# DDR16SS_DDR16SS_CTLPHY_WRAP_CTL_CFG_CTLCFG_0F308000h register map
Vendor: Texas Instruments
Peripheral module from a debugger description file (folder am62L).
Registers are 32-bit, read-write, reset 0x0 unless marked. A register's access mark holds for its fields unless they carry their own. Offsets are as the file gives them; lines under a group give offsets from that group; [hi:lo] are bit positions; {n}, {i} and the like mark numbered series; 'fields as' and 'values as' point back to an identical list; <NAME> marks a mode.

## DDR16SS_CTLPHY_WRAP_CTL_CFG_CTLCFG (part 1 of 11)
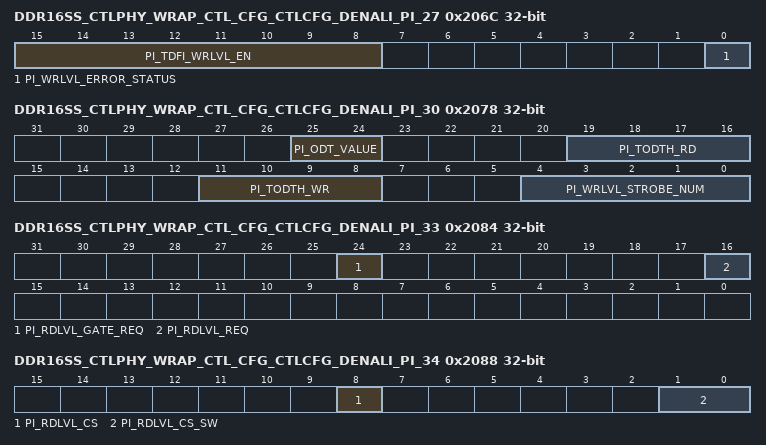
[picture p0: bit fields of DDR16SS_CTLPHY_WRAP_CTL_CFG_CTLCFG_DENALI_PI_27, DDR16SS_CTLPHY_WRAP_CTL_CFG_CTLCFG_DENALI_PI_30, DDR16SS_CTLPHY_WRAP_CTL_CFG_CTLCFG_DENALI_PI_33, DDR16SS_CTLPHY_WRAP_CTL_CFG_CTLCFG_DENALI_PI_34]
0x206C DDR16SS_CTLPHY_WRAP_CTL_CFG_CTLCFG_DENALI_PI_27 access per field
  [15:8] PI_TDFI_WRLVL_EN rw — Defines the DFI tWRLVL_EN timing parameter [in DFI clocks], the minimum cycles from a dfi_wrlvl_en assertion to the first dfi_wrlvl_strobe assertion. Reset Source: ctl_amod_g_rst_n
  [0] PI_WRLVL_ERROR_STATUS ro — Holds the error associated with the write level error interrupt. Bit [0] set indicates a TDFI_WRLVL_MAX parameter violation and bit [1] set indicates a TDFI_WRLVL_RESP parameter violation. READ-ONLY Reset Source: ctl_amod_g_rst_n
0x2070 DDR16SS_CTLPHY_WRAP_CTL_CFG_CTLCFG_DENALI_PI_28
  [31:0] PI_TDFI_WRLVL_RESP — Defines the DFI tWRLVL_RESP timing parameter [in DFI clocks], the maximum cycles between a dfi_wrlvl_req assertion and a dfi_wrlvl_en assertion. Reset Source: ctl_amod_g_rst_n
0x2074 DDR16SS_CTLPHY_WRAP_CTL_CFG_CTLCFG_DENALI_PI_29
  [31:0] PI_TDFI_WRLVL_MAX — Defines the DFI tWRLVL_MAX timing parameter [in DFI clocks], the maximum cycles between a dfi_wrlvl_en assertion and a valid dfi_wrlvl_resp. Reset Source: ctl_amod_g_rst_n
0x2078 DDR16SS_CTLPHY_WRAP_CTL_CFG_CTLCFG_DENALI_PI_30
  [25:24] PI_ODT_VALUE — When using LPDDR4, this value will be driven out on the dfi_odt signal. Reset Source: ctl_amod_g_rst_n
  [19:16] PI_TODTH_RD — Defines the minimum DRAM cycles of ODT high time for a read command, in memory clocks. Reset Source: ctl_amod_g_rst_n
  [11:8] PI_TODTH_WR — Defines the minimum DRAM cycles of ODT high time for a write command, in memory clocks. Reset Source: ctl_amod_g_rst_n
  [4:0] PI_WRLVL_STROBE_NUM — Defines the number of write leveling strobes generated. Reset Source: ctl_amod_g_rst_n
0x207C DDR16SS_CTLPHY_WRAP_CTL_CFG_CTLCFG_DENALI_PI_31
  [1:0] PI_ADDRESS_MIRRORING — Indicates which chip selects support address mirroring. Bit [0] controls cs0, bit [1] controls cs1, etc. Set each bit to 1 to enable. Reset Source: ctl_amod_g_rst_n
0x2080 DDR16SS_CTLPHY_WRAP_CTL_CFG_CTLCFG_DENALI_PI_32
  [25:0] PI_CA_PARITY_ERROR_INJECT — Selects bit to corrupt on the CA bus for CA parity error injection. Reset Source: ctl_amod_g_rst_n
0x2084 DDR16SS_CTLPHY_WRAP_CTL_CFG_CTLCFG_DENALI_PI_33 wo
  [24] PI_RDLVL_GATE_REQ — User request to initiate gate training. Set to 1 to trigger. WRITE-ONLY Reset Source: ctl_amod_g_rst_n
  [16] PI_RDLVL_REQ — User request to initiate data eye training. Set to 1 to trigger. WRITE-ONLY Reset Source: ctl_amod_g_rst_n
0x2088 DDR16SS_CTLPHY_WRAP_CTL_CFG_CTLCFG_DENALI_PI_34
  [8] PI_RDLVL_CS — Specifies the target chip select for the data eye training operation initiated through the RDLVL_REQ parameter or the gate training operation initiated through the RDLVL_GATE_REQ parameter. Reset Source: ctl_amod_g_rst_n
  [1:0] PI_RDLVL_CS_SW — Specifies the target chip select for the data eye training operation initiated through the RDLVL_REQ parameter or the gate training operation initiated through the RDLVL_GATE_REQ parameter. Reset Source: ctl_amod_g_rst_n
{0x2000+4i} DDR16SS_CTLPHY_WRAP_CTL_CFG_CTLCFG_DENALI_PI_{i} (i=35..42)
  [31:0] PI_RDLVL_PAT_{i-35} — Non-default pattern {i-35} used for read data eye training of DDR4 or LPDDR4, and read dbi training of DDR4. Reset Source: ctl_amod_g_rst_n
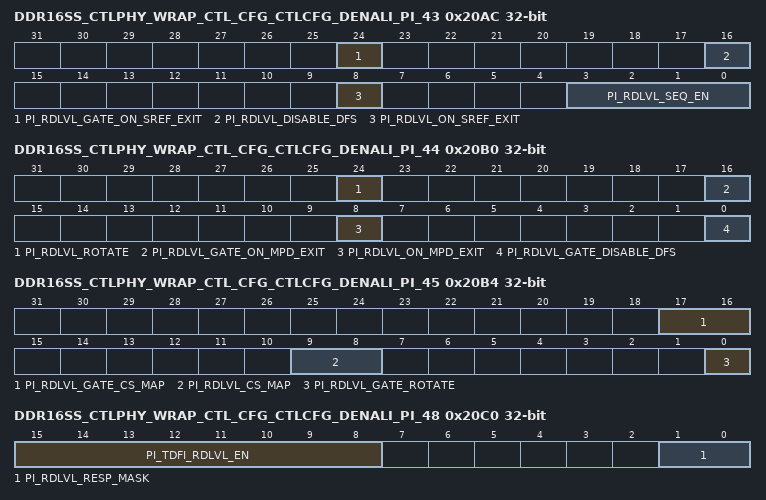
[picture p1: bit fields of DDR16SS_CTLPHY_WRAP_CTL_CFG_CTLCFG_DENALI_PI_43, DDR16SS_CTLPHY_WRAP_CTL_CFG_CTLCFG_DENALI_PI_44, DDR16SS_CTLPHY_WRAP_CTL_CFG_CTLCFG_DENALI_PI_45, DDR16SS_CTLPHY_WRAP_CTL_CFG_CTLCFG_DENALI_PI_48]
0x20AC DDR16SS_CTLPHY_WRAP_CTL_CFG_CTLCFG_DENALI_PI_43
  [24] PI_RDLVL_GATE_ON_SREF_EXIT — Enables automatic gate training on a self-refresh exit. Set to 1 to enable. Reset Source: ctl_amod_g_rst_n
  [16] PI_RDLVL_DISABLE_DFS — Disables automatic data eye training on freq change. Set to 1 to disable rdlvl on dfs,Set to 0 to enable rdlvl on dfs. Reset Source: ctl_amod_g_rst_n
  [8] PI_RDLVL_ON_SREF_EXIT — Enables automatic data eye training on a self-refresh exit. Set to 1 to enable. Reset Source: ctl_amod_g_rst_n
  [3:0] PI_RDLVL_SEQ_EN — Specifies the pattern, format and MPR for data eye training. Reset Source: ctl_amod_g_rst_n
0x20B0 DDR16SS_CTLPHY_WRAP_CTL_CFG_CTLCFG_DENALI_PI_44
  [24] PI_RDLVL_ROTATE — Enables rotational CS for interval data eye training. Set to 1 for rotating CS. Reset Source: ctl_amod_g_rst_n
  [16] PI_RDLVL_GATE_ON_MPD_EXIT — Enables automatic gate training on a maximum power down mode exit. Set to 1 to enable. Reset Source: ctl_amod_g_rst_n
  [8] PI_RDLVL_ON_MPD_EXIT — Enables automatic data eye training on a maximum power down mode exit. Set to 1 to enable. Reset Source: ctl_amod_g_rst_n
  [0] PI_RDLVL_GATE_DISABLE_DFS — Disables automatic gate training on freq change. Set to 1 to disable rdlvl_gate on dfs,Set to 0 to enable rdlvl_gate on dfs. Reset Source: ctl_amod_g_rst_n
0x20B4 DDR16SS_CTLPHY_WRAP_CTL_CFG_CTLCFG_DENALI_PI_45
  [17:16] PI_RDLVL_GATE_CS_MAP — Defines the chip select map for gate training operations. Bit [0] controls cs0, bit [1] controls cs1, etc. Set each bit to 1 to enable chip for gate training. Reset Source: ctl_amod_g_rst_n
  [9:8] PI_RDLVL_CS_MAP — Defines the chip select map for data eye training operations. Bit [0] controls cs0, bit [1] controls cs1, etc. Set each bit to 1 to enable chip for data eye training. Reset Source: ctl_amod_g_rst_n
  [0] PI_RDLVL_GATE_ROTATE — Enables rotational CS for interval gate training. Set to 1 for rotating CS. Reset Source: ctl_amod_g_rst_n
0x20B8 DDR16SS_CTLPHY_WRAP_CTL_CFG_CTLCFG_DENALI_PI_46
  [9:0] PI_TDFI_RDLVL_RR — Defines the DFI tRDLVL_RR timing parameter [in DFI clocks], the minimum cycles between read commands. Reset Source: ctl_amod_g_rst_n
0x20BC DDR16SS_CTLPHY_WRAP_CTL_CFG_CTLCFG_DENALI_PI_47
  [31:0] PI_TDFI_RDLVL_RESP — Defines the DFI tRDLVL_RESP timing parameter [in DFI clocks], the maximum cycles between a dfi_rdlvl_req or dfi_rdlvl_gate_req assertion and a dfi_rdlvl_en or dfi_rdlvl_gate_en assertion. Reset Source: ctl_amod_g_rst_n
0x20C0 DDR16SS_CTLPHY_WRAP_CTL_CFG_CTLCFG_DENALI_PI_48
  [15:8] PI_TDFI_RDLVL_EN — Defines the DFI tRDLVL_EN timing parameter [in DFI clocks], the minimum cycles from a dfi_rdlvl_en or dfi_rdlvl_gate_en assertion to the first read or MRR. Set to 1 means the minium value[1 cycle], set to 0 means the maxium value Reset Source: ctl_amod_g_rst_n
  [1:0] PI_RDLVL_RESP_MASK — Mask for the dfi_rdlvl_resp signal during data eye training. Reset Source: ctl_amod_g_rst_n
0x20C4 DDR16SS_CTLPHY_WRAP_CTL_CFG_CTLCFG_DENALI_PI_49
  [31:0] PI_TDFI_RDLVL_MAX — Defines the DFI tRDLVL_MAX timing parameter [in DFI clocks], the maximum cycles between a dfi_rdlvl_en or dfi_rdlvl_gate_en assertion and a valid dfi_rdlvl_resp. Reset Source: ctl_amod_g_rst_n
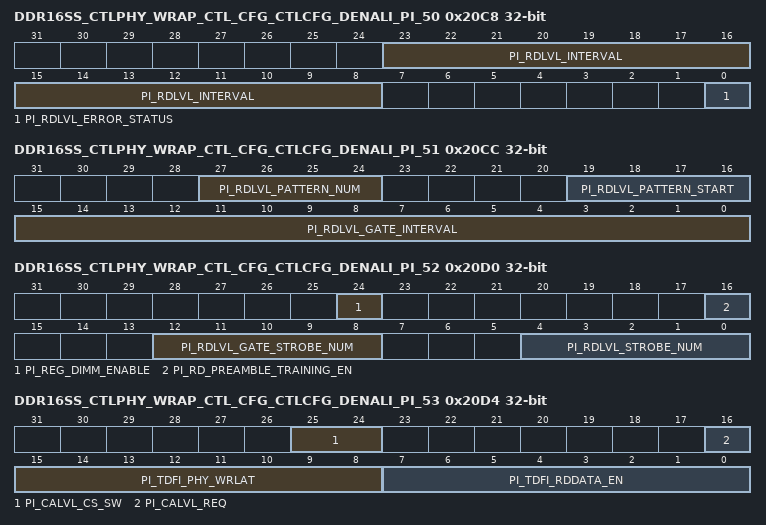
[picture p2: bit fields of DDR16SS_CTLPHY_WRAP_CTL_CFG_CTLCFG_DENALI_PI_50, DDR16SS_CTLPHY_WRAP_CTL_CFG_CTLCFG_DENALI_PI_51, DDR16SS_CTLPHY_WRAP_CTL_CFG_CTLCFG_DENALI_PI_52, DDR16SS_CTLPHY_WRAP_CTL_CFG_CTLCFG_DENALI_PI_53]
0x20C8 DDR16SS_CTLPHY_WRAP_CTL_CFG_CTLCFG_DENALI_PI_50 access per field
  [23:8] PI_RDLVL_INTERVAL rw — Number of long count sequences counted between automatic data eye training commands. Reset Source: ctl_amod_g_rst_n
  [0] PI_RDLVL_ERROR_STATUS ro — Holds the error associated with the data eye training error or gate training error interrupt. Uppermost bit set indicates a TDFI_RDLVL_RESP parameter violation. Next uppermost bit set indicates a TDFI_RDLVL_MAX parameter violation. Lower bits are reserved. READ-ONLY Reset Source: ctl_amod_g_rst_n
0x20CC DDR16SS_CTLPHY_WRAP_CTL_CFG_CTLCFG_DENALI_PI_51
  [27:24] PI_RDLVL_PATTERN_NUM — Defines the number of pattern supported in read leveling. Reset Source: ctl_amod_g_rst_n
  [19:16] PI_RDLVL_PATTERN_START — Defines the start pattern in read leveling. Reset Source: ctl_amod_g_rst_n
  [15:0] PI_RDLVL_GATE_INTERVAL — Number of long count sequences counted between automatic gate training commands. Reset Source: ctl_amod_g_rst_n
0x20D0 DDR16SS_CTLPHY_WRAP_CTL_CFG_CTLCFG_DENALI_PI_52
  [24] PI_REG_DIMM_ENABLE — Enable registered DIMM operation. Set to 1 to enable. Reset Source: ctl_amod_g_rst_n
  [16] PI_RD_PREAMBLE_TRAINING_EN — Enable read preamble training during gate training. Set to 1 to enable. Reset Source: ctl_amod_g_rst_n
  [12:8] PI_RDLVL_GATE_STROBE_NUM — Defines the number of back to back MPC command in one read process in read gate training. Reset Source: ctl_amod_g_rst_n
  [4:0] PI_RDLVL_STROBE_NUM — Defines the number of back to back MPC command in one read process in read eye training. Reset Source: ctl_amod_g_rst_n
0x20D4 DDR16SS_CTLPHY_WRAP_CTL_CFG_CTLCFG_DENALI_PI_53 access per field
  [25:24] PI_CALVL_CS_SW rw — Specifies the target chip select for the CA training operation initiated through the CALVL_REQ parameter. Reset Source: ctl_amod_g_rst_n
  [16] PI_CALVL_REQ wo — User request to initiate CA training. Set to 1 to trigger. WRITE-ONLY Reset Source: ctl_amod_g_rst_n
  [15:8] PI_TDFI_PHY_WRLAT ro — Holds the calculated DFI tPHY_WRLAT timing parameter [in DFI PHY clocks], the maximum cycles between a write command and a dfi_wrdata_en assertion. READ-ONLY Reset Source: ctl_amod_g_rst_n
  [7:0] PI_TDFI_RDDATA_EN ro — Holds the calculated DFI tRDDATA_EN timing parameter [in DFI PHY clocks], the maximum cycles between a read command and a dfi_rddata_en assertion. READ-ONLY Reset Source: ctl_amod_g_rst_n
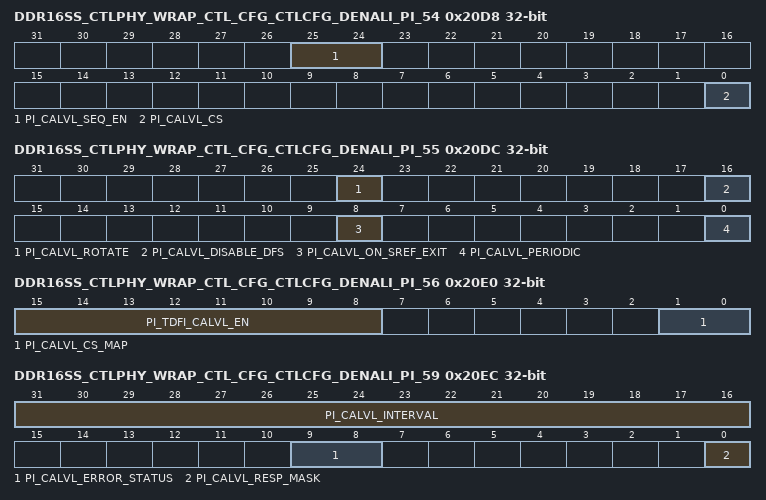
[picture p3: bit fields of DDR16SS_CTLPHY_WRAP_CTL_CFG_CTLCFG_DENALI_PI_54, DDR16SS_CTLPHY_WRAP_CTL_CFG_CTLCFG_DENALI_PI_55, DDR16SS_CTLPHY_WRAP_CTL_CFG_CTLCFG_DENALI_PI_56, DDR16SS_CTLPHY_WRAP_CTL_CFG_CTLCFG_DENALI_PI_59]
0x20D8 DDR16SS_CTLPHY_WRAP_CTL_CFG_CTLCFG_DENALI_PI_54
  [25:24] PI_CALVL_SEQ_EN — Specifies which CA training patterns will be used. Set to 0 for pattern 0 only, set to 1 for patterns 0 and 1, set to 2 for patterns 0, 1 and 2, or set to 3 for all patterns. Reset Source: ctl_amod_g_rst_n
  [0] PI_CALVL_CS — Specifies the target chip select for the CA training operation initiated through the CALVL_REQ parameter. Reset Source: ctl_amod_g_rst_n
0x20DC DDR16SS_CTLPHY_WRAP_CTL_CFG_CTLCFG_DENALI_PI_55
  [24] PI_CALVL_ROTATE — Enables rotational CS for interval CA training. Set to 1 for rotating CS. Reset Source: ctl_amod_g_rst_n
  [16] PI_CALVL_DISABLE_DFS — Disables automatic CA training on freq change. Set to 1 to disable CA training on dfs, Set to 0 to enable CA training . Reset Source: ctl_amod_g_rst_n
  [8] PI_CALVL_ON_SREF_EXIT — Enables automatic CA training on a self-refresh exit. Set to 1 to enable. Reset Source: ctl_amod_g_rst_n
  [0] PI_CALVL_PERIODIC — Enables the use of the dfi_lvl_periodic signal during CA training. Set to 1 to enable. Reset Source: ctl_amod_g_rst_n
0x20E0 DDR16SS_CTLPHY_WRAP_CTL_CFG_CTLCFG_DENALI_PI_56
  [15:8] PI_TDFI_CALVL_EN — Defines the DFI tCALVL_EN timing parameter [in DFI clocks], the minimum cycles between a dfi_calvl_en assertion and a dfi_cke de-assertion. Reset Source: ctl_amod_g_rst_n
  [1:0] PI_CALVL_CS_MAP — Defines the chip select map for CA training operations. Bit [0] controls cs0, bit [1] controls cs1, etc. Set each bit to 1 to enable chip for CA training. Reset Source: ctl_amod_g_rst_n
0x20E4 DDR16SS_CTLPHY_WRAP_CTL_CFG_CTLCFG_DENALI_PI_57
  [31:0] PI_TDFI_CALVL_RESP — Defines the DFI tCALVL_RESP timing parameter [in DFI clocks], the maximum cycles between a dfi_calvl_req assertion and a dfi_calvl_en assertion. Reset Source: ctl_amod_g_rst_n
0x20E8 DDR16SS_CTLPHY_WRAP_CTL_CFG_CTLCFG_DENALI_PI_58
  [31:0] PI_TDFI_CALVL_MAX — Defines the DFI tCALVL_MAX timing parameter [in DFI clocks], the maximum cycles between a dfi_calvl_en assertion and a valid dfi_calvl_resp. Reset Source: ctl_amod_g_rst_n
0x20EC DDR16SS_CTLPHY_WRAP_CTL_CFG_CTLCFG_DENALI_PI_59 access per field
  [31:16] PI_CALVL_INTERVAL rw — Number of long count sequences counted between automatic CA training commands. Reset Source: ctl_amod_g_rst_n
  [9:8] PI_CALVL_ERROR_STATUS ro — Holds the error associated with the CA training error interrupt. Bit [0] set indicates a TDFI_CALVL_RESP parameter violation and bit [1] set indicates a TDFI_CALVL_MAX parameter violation. READ-ONLY Reset Source: ctl_amod_g_rst_n
  [0] PI_CALVL_RESP_MASK rw — Mask for the dfi_calvl_resp signal during CA training. Reset Source: ctl_amod_g_rst_n
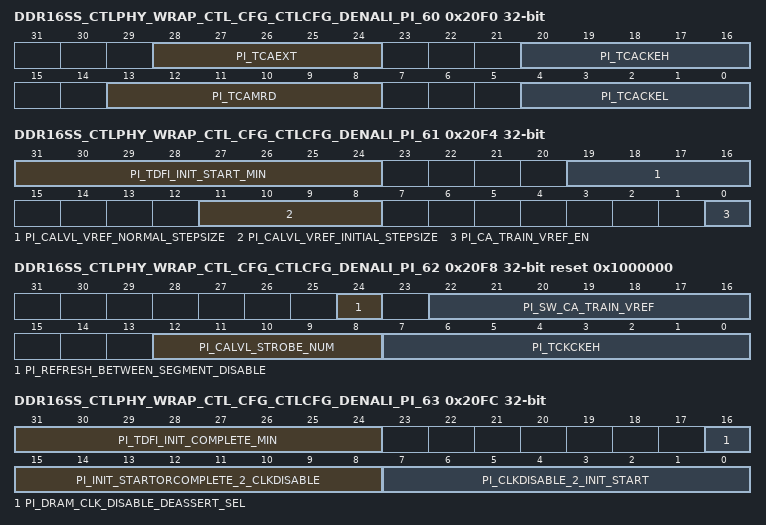
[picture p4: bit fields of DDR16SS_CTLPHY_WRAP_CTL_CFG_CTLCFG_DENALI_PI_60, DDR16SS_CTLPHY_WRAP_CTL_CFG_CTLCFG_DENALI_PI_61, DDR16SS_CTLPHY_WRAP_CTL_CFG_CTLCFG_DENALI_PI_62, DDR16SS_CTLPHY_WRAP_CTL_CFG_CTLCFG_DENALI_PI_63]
0x20F0 DDR16SS_CTLPHY_WRAP_CTL_CFG_CTLCFG_DENALI_PI_60
  [28:24] PI_TCAEXT — DRAM tCAEXT value in memory cycles. Reset Source: ctl_amod_g_rst_n
  [20:16] PI_TCACKEH — DRAM tCACKEH value in memory cycles. Reset Source: ctl_amod_g_rst_n
  [13:8] PI_TCAMRD — DRAM tCAMRD value in memory cycles. Reset Source: ctl_amod_g_rst_n
  [4:0] PI_TCACKEL — DRAM tCACKEL value in memory cycles. Reset Source: ctl_amod_g_rst_n
0x20F4 DDR16SS_CTLPHY_WRAP_CTL_CFG_CTLCFG_DENALI_PI_61
  [31:24] PI_TDFI_INIT_START_MIN — Minimum number of DFI clocks before dfi_init_start can be driven after a previous command/training event. Reset Source: ctl_amod_g_rst_n
  [19:16] PI_CALVL_VREF_NORMAL_STEPSIZE — The adjust step for the post-initial Vref[ca] training. Reset Source: ctl_amod_g_rst_n
  [11:8] PI_CALVL_VREF_INITIAL_STEPSIZE — The adjust step for the initial Vref[ca] training. Reset Source: ctl_amod_g_rst_n
  [0] PI_CA_TRAIN_VREF_EN — Control for VREF training during CA training post power-on initialization. Set to enable VREF training. Reset Source: ctl_amod_g_rst_n
0x20F8 DDR16SS_CTLPHY_WRAP_CTL_CFG_CTLCFG_DENALI_PI_62 reset 0x1000000
  [24] PI_REFRESH_BETWEEN_SEGMENT_DISABLE — Disable the refresh between CA first and second segment training. Set to 1 to disable. Reset Source: ctl_amod_g_rst_n
  [22:16] PI_SW_CA_TRAIN_VREF — The Vref value which is set for SW step by step CA training. Reset Source: ctl_amod_g_rst_n
  [12:8] PI_CALVL_STROBE_NUM — The consecutive dfi_calvl_strobe number when updating the CA vref data. Reset Source: ctl_amod_g_rst_n
  [7:0] PI_TCKCKEH — DRAM tCKELCK Clock and command valid before CKE HIGH. Reset Source: ctl_amod_g_rst_n
0x20FC DDR16SS_CTLPHY_WRAP_CTL_CFG_CTLCFG_DENALI_PI_63
  [31:24] PI_TDFI_INIT_COMPLETE_MIN — Minimum number of DFI clocks from dfi_init_complete to a command/training event. Reset Source: ctl_amod_g_rst_n
  [16] PI_DRAM_CLK_DISABLE_DEASSERT_SEL — Indicate dfi_dram_clk_disable deassert following dfi_init_start deassert or dfi_init_complete assert. Set to 0: dfi_dram_clk_disable deassert following dfi_init_start deassert. Set to 1: dfi_dram_clk_disable deassert following dfi_init_complete assert. Reset Source: ctl_amod_g_rst_n
  [15:8] PI_INIT_STARTORCOMPLETE_2_CLKDISABLE — Defines the delay from deasserting of dfi_init_start or asserting of dfi_init_complete to deasserting of dfi_dram_clk_disable in DFI clock. Reset Source: ctl_amod_g_rst_n
  [7:0] PI_CLKDISABLE_2_INIT_START — Defines the delay from the asserting of dfi_dram_clk_disable to the asserting of dfi_init_start in DFI clock. Reset Source: ctl_amod_g_rst_n
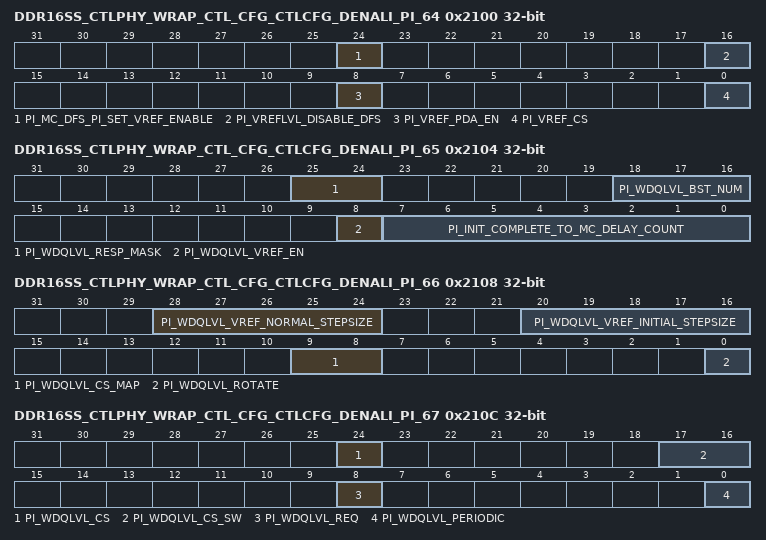
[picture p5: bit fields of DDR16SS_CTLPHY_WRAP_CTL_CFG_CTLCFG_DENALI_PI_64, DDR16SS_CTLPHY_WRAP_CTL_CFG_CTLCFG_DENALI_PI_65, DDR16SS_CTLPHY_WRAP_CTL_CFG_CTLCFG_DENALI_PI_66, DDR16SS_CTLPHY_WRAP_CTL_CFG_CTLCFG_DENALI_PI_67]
0x2100 DDR16SS_CTLPHY_WRAP_CTL_CFG_CTLCFG_DENALI_PI_64
  [24] PI_MC_DFS_PI_SET_VREF_ENABLE — Enable the PI to set VREF value after DFS issued by MC. MR12 and MR14 for LPDDR4. MR6 for DDR4. 1 means disable. Reset Source: ctl_amod_g_rst_n
  [16] PI_VREFLVL_DISABLE_DFS — Disables automatic VREF training on freq change. Set to 1 to disable. Reset Source: ctl_amod_g_rst_n
  [8] PI_VREF_PDA_EN — Enable per-DRAM addressability during VREF training. Set to 1 to enable. Reset Source: ctl_amod_g_rst_n
  [0] PI_VREF_CS — Specifies the target chip select for the VREF training operation. Reset Source: ctl_amod_g_rst_n
0x2104 DDR16SS_CTLPHY_WRAP_CTL_CFG_CTLCFG_DENALI_PI_65
  [25:24] PI_WDQLVL_RESP_MASK — Write DQ training response mask. When set to 1, the dfi_wdqlvl_en of the slice is not asserted. Reset Source: ctl_amod_g_rst_n
  [18:16] PI_WDQLVL_BST_NUM — Defines the number of write/read bursts issued at each step in write DQ training. Reset Source: ctl_amod_g_rst_n
  [8] PI_WDQLVL_VREF_EN — Control for VREF training as part of non-initialization write DQ training. Reset Source: ctl_amod_g_rst_n
  [7:0] PI_INIT_COMPLETE_TO_MC_DELAY_COUNT — It controls the time PI bypass CKE at the beginning of PI mask dfi_init_complete to controller. Reset Source: ctl_amod_g_rst_n
0x2108 DDR16SS_CTLPHY_WRAP_CTL_CFG_CTLCFG_DENALI_PI_66
  [28:24] PI_WDQLVL_VREF_NORMAL_STEPSIZE — Write DQ training vref step size for post_initial training. Reset Source: ctl_amod_g_rst_n
  [20:16] PI_WDQLVL_VREF_INITIAL_STEPSIZE — Write DQ training vref step size for initial training. Reset Source: ctl_amod_g_rst_n
  [9:8] PI_WDQLVL_CS_MAP — Map of CS's included in write DQ training sequence. Reset Source: ctl_amod_g_rst_n
  [0] PI_WDQLVL_ROTATE — Enables write DQ training rotate for interval training. Reset Source: ctl_amod_g_rst_n
0x210C DDR16SS_CTLPHY_WRAP_CTL_CFG_CTLCFG_DENALI_PI_67 access per field
  [24] PI_WDQLVL_CS rw — Write DQ training target chip select. Reset Source: ctl_amod_g_rst_n
  [17:16] PI_WDQLVL_CS_SW rw — Write DQ training target chip select. Reset Source: ctl_amod_g_rst_n
  [8] PI_WDQLVL_REQ wo — SW write to initiate Write DQ training request. WRITE-ONLY Reset Source: ctl_amod_g_rst_n
  [0] PI_WDQLVL_PERIODIC rw — Enables periodic write DQ training. Reset Source: ctl_amod_g_rst_n
0x2110 DDR16SS_CTLPHY_WRAP_CTL_CFG_CTLCFG_DENALI_PI_68
  [7:0] PI_TDFI_WDQLVL_EN — DFI timing param tWDQLVL_EN. Minimum number of DFI clocks required after the write DQ training enable signal is asserted until the first write command may be asserted. Reset Source: ctl_amod_g_rst_n
0x2114 DDR16SS_CTLPHY_WRAP_CTL_CFG_CTLCFG_DENALI_PI_69
  [31:0] PI_TDFI_WDQLVL_RESP — DFI timing param tWDQLVL_RESP. Maximum number of DFI clocks that may occur between a write DQ training request and the associated mode enable. Reset Source: ctl_amod_g_rst_n
0x2118 DDR16SS_CTLPHY_WRAP_CTL_CFG_CTLCFG_DENALI_PI_70
  [31:0] PI_TDFI_WDQLVL_MAX — DFI timing param tWDQLVL_MAX. Maximum number of DFI clocks that the PI will wait for a response from the PHY. Reset Source: ctl_amod_g_rst_n
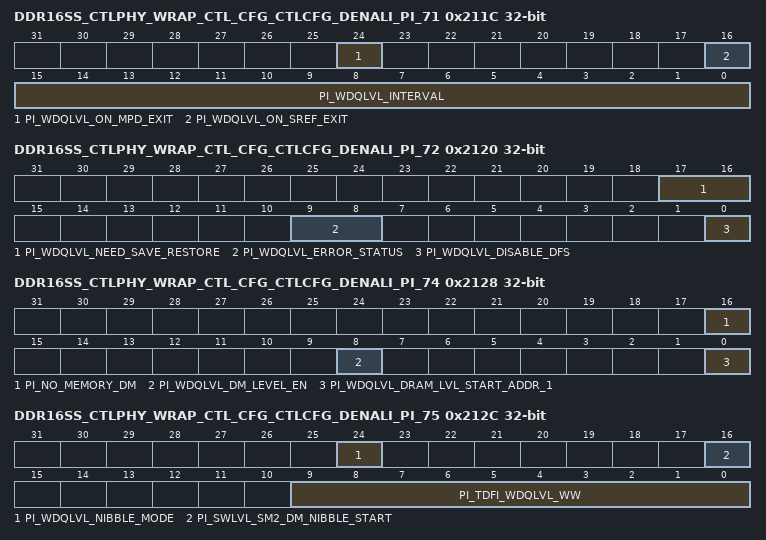
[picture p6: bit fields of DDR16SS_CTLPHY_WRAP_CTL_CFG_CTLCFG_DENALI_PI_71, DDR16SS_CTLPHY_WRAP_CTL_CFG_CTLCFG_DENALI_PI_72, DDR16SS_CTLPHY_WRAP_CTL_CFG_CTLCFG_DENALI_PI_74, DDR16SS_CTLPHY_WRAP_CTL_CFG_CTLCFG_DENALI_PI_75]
0x211C DDR16SS_CTLPHY_WRAP_CTL_CFG_CTLCFG_DENALI_PI_71
  [24] PI_WDQLVL_ON_MPD_EXIT — Issue a write DQ training command on maximum power saving mode exit. Reset Source: ctl_amod_g_rst_n
  [16] PI_WDQLVL_ON_SREF_EXIT — Issue a write DQ training command on self-refresh exit. Reset Source: ctl_amod_g_rst_n
  [15:0] PI_WDQLVL_INTERVAL — Sets the maximum number of long count sequences allowed between automatic write DQ training operations. Reset Source: ctl_amod_g_rst_n
0x2120 DDR16SS_CTLPHY_WRAP_CTL_CFG_CTLCFG_DENALI_PI_72 access per field
  [17:16] PI_WDQLVL_NEED_SAVE_RESTORE rw — Enables the use of functional DRAM address space for write DQ training, 1 = enable, not for LPDDR4. Reset Source: ctl_amod_g_rst_n
  [9:8] PI_WDQLVL_ERROR_STATUS ro — Holds the error associated with the write dq level error interrupt. Bit [0] set indicates a PI_TDFI_WDQLVL_MAX parameter violation and bit [1] set indicates a PI_TDFI_WDQLVL_RESP parameter violation. READ-ONLY. Reset Source: ctl_amod_g_rst_n
  [0] PI_WDQLVL_DISABLE_DFS rw — Disable automatic write DQ training on freq change. Set to 1 to disable. Reset Source: ctl_amod_g_rst_n
0x2124 DDR16SS_CTLPHY_WRAP_CTL_CFG_CTLCFG_DENALI_PI_73
  [31:0] PI_WDQLVL_DRAM_LVL_START_ADDR_0 — Start address of WDQ leveling, not for LPDDR4. Reset Source: ctl_amod_g_rst_n
0x2128 DDR16SS_CTLPHY_WRAP_CTL_CFG_CTLCFG_DENALI_PI_74
  [16] PI_NO_MEMORY_DM — Defines if the attached memory supports the Data Mask function, 1 = not supported. Reset Source: ctl_amod_g_rst_n
  [8] PI_WDQLVL_DM_LEVEL_EN — Enable for write DM training as part of the write DQ training, not for LPDDR4. Reset Source: ctl_amod_g_rst_n
  [0] PI_WDQLVL_DRAM_LVL_START_ADDR_1 — Start address of WDQ leveling, not for LPDDR4. Reset Source: ctl_amod_g_rst_n
0x212C DDR16SS_CTLPHY_WRAP_CTL_CFG_CTLCFG_DENALI_PI_75 access per field
  [24] PI_WDQLVL_NIBBLE_MODE rw — WDQ Training Nibble mode indication. When set to 1, nibble mode is enabled, and the training timing is doubled. Reset Source: ctl_amod_g_rst_n
  [16] PI_SWLVL_SM2_DM_NIBBLE_START wo — Start command for stage 2, when in the process of DM leveling or nibble mode. WRITE-ONLY Reset Source: ctl_amod_g_rst_n
  [9:0] PI_TDFI_WDQLVL_WW rw — Minimum number of DFI clocks to be inserted between write commands during the DM portion of write DQ training. Reset Source: ctl_amod_g_rst_n
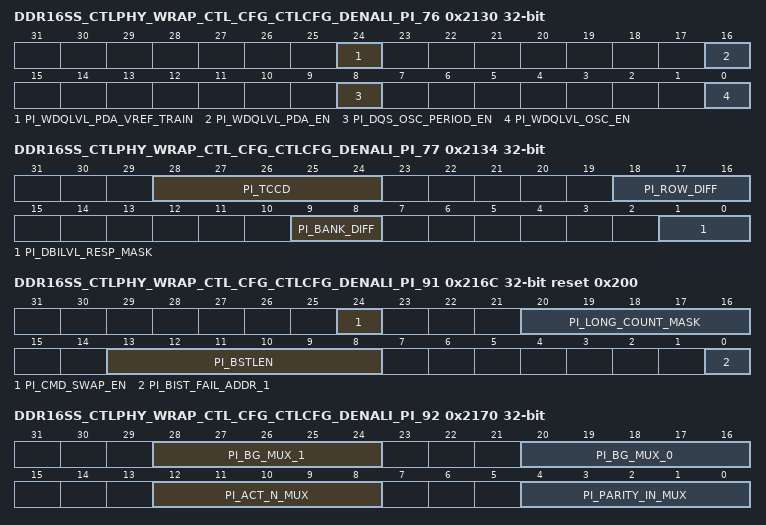
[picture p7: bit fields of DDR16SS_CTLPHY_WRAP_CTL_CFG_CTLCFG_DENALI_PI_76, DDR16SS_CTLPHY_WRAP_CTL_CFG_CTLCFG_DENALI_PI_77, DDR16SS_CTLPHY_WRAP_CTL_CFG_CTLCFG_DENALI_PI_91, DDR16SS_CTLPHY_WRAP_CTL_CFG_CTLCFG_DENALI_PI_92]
0x2130 DDR16SS_CTLPHY_WRAP_CTL_CFG_CTLCFG_DENALI_PI_76
  [24] PI_WDQLVL_PDA_VREF_TRAIN — Enable for the use of PDA to set the VREF during write DQ training, 1 = enabled. Reset Source: ctl_amod_g_rst_n
  [16] PI_WDQLVL_PDA_EN — Enable for the use of write DQ training for PDA mode, 1 = enabled. Reset Source: ctl_amod_g_rst_n
  [8] PI_DQS_OSC_PERIOD_EN — Enable for DQS oscillator triggered periodic write DQ training, 1 = enabled. Reset Source: ctl_amod_g_rst_n
  [0] PI_WDQLVL_OSC_EN — Enable for DQS oscillator triggered write DQ training, 1 = enabled. Reset Source: ctl_amod_g_rst_n
0x2134 DDR16SS_CTLPHY_WRAP_CTL_CFG_CTLCFG_DENALI_PI_77
  [28:24] PI_TCCD — DRAM CAS-to-CAS value in cycles. Reset Source: ctl_amod_g_rst_n
  [18:16] PI_ROW_DIFF — Difference between number of address pins available and number being used. Reset Source: ctl_amod_g_rst_n
  [9:8] PI_BANK_DIFF — Difference between number of bank pins available and number being used. Reset Source: ctl_amod_g_rst_n
  [1:0] PI_DBILVL_RESP_MASK — Mask for the dfi_rdlvl_resp signal during read dbi training. Reset Source: ctl_amod_g_rst_n
{0x2000+4i} DDR16SS_CTLPHY_WRAP_CTL_CFG_CTLCFG_DENALI_PI_{i} access not given reset not defined (i=78..82)
0x214C DDR16SS_CTLPHY_WRAP_CTL_CFG_CTLCFG_DENALI_PI_83 ro
  [29:0] PI_INT_STATUS — Status of interrupt features in the PI. READ-ONLY Reset Source: ctl_amod_g_rst_n
0x2150 DDR16SS_CTLPHY_WRAP_CTL_CFG_CTLCFG_DENALI_PI_84 wo
  [28:0] PI_INT_ACK — Clear the corresponding interrupt bit of the PI_INT_STATUS parameter. WRITE-ONLY Reset Source: ctl_amod_g_rst_n
0x2154 DDR16SS_CTLPHY_WRAP_CTL_CFG_CTLCFG_DENALI_PI_85
  [29:0] PI_INT_MASK — Mask for PI_int signals from the PI_INT_STATUS parameter. Reset Source: ctl_amod_g_rst_n
0x2158 DDR16SS_CTLPHY_WRAP_CTL_CFG_CTLCFG_DENALI_PI_86 ro
  [31:0] PI_BIST_EXP_DATA_0 — Expected data on BIST error. READ-ONLY Reset Source: ctl_amod_g_rst_n
0x215C DDR16SS_CTLPHY_WRAP_CTL_CFG_CTLCFG_DENALI_PI_87 ro
  [31:0] PI_BIST_EXP_DATA_1 — Expected data on BIST error. READ-ONLY Reset Source: ctl_amod_g_rst_n
0x2160 DDR16SS_CTLPHY_WRAP_CTL_CFG_CTLCFG_DENALI_PI_88 ro
  [31:0] PI_BIST_FAIL_DATA_0 — Actual data on BIST error. READ-ONLY Reset Source: ctl_amod_g_rst_n
0x2164 DDR16SS_CTLPHY_WRAP_CTL_CFG_CTLCFG_DENALI_PI_89 ro
  [31:0] PI_BIST_FAIL_DATA_1 — Actual data on BIST error. READ-ONLY Reset Source: ctl_amod_g_rst_n
0x2168 DDR16SS_CTLPHY_WRAP_CTL_CFG_CTLCFG_DENALI_PI_90 ro
  [31:0] PI_BIST_FAIL_ADDR_0 — The burst aligned address of BIST error. READ-ONLY Reset Source: ctl_amod_g_rst_n
0x216C DDR16SS_CTLPHY_WRAP_CTL_CFG_CTLCFG_DENALI_PI_91 access per field reset 0x200
  [24] PI_CMD_SWAP_EN rw — Command pin swap function enable Reset Source: ctl_amod_g_rst_n
  [20:16] PI_LONG_COUNT_MASK rw — Reduces the length of the long counter from 1024 cycles. Reset Source: ctl_amod_g_rst_n
  [13:8] PI_BSTLEN rw — Encoded burst length sent to DRAMs during initialization. Reset Source: ctl_amod_g_rst_n
  [0] PI_BIST_FAIL_ADDR_1 ro — The burst aligned address of BIST error. READ-ONLY Reset Source: ctl_amod_g_rst_n
0x2170 DDR16SS_CTLPHY_WRAP_CTL_CFG_CTLCFG_DENALI_PI_92
  [28:24] PI_BG_MUX_1 — Command pin BG_1 mux selector Reset Source: ctl_amod_g_rst_n
  [20:16] PI_BG_MUX_0 — Command pin BG_0 mux selector Reset Source: ctl_amod_g_rst_n
  [12:8] PI_ACT_N_MUX — Command pin ACT_N mux selector Reset Source: ctl_amod_g_rst_n
  [4:0] PI_PARITY_IN_MUX — Command pin parity mux selector Reset Source: ctl_amod_g_rst_n
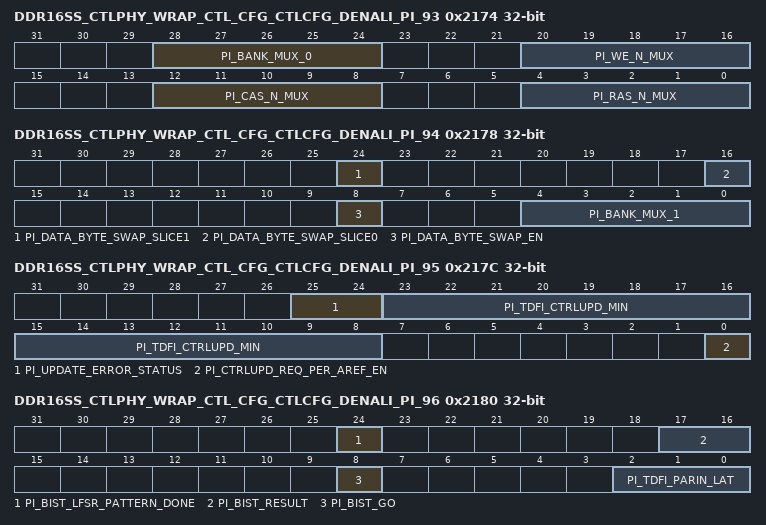
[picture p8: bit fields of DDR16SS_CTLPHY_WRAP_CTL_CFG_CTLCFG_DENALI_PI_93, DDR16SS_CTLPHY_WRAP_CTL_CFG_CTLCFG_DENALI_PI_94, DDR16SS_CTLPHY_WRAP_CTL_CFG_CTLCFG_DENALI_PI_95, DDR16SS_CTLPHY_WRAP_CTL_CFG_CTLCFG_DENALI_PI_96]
0x2174 DDR16SS_CTLPHY_WRAP_CTL_CFG_CTLCFG_DENALI_PI_93
  [28:24] PI_BANK_MUX_0 — Command pin BANK_0 mux selector Reset Source: ctl_amod_g_rst_n
  [20:16] PI_WE_N_MUX — Command pin WE_N mux selector Reset Source: ctl_amod_g_rst_n
  [12:8] PI_CAS_N_MUX — Command pin CAS_N mux selector Reset Source: ctl_amod_g_rst_n
  [4:0] PI_RAS_N_MUX — Command pin RAS_N mux selector Reset Source: ctl_amod_g_rst_n
0x2178 DDR16SS_CTLPHY_WRAP_CTL_CFG_CTLCFG_DENALI_PI_94
  [24] PI_DATA_BYTE_SWAP_SLICE1 — DATA pin 1 mux selector Reset Source: ctl_amod_g_rst_n
  [16] PI_DATA_BYTE_SWAP_SLICE0 — DATA pin 0 mux selector Reset Source: ctl_amod_g_rst_n
  [8] PI_DATA_BYTE_SWAP_EN — DATA pin swap function enable Reset Source: ctl_amod_g_rst_n
  [4:0] PI_BANK_MUX_1 — Command pin BANK_1 mux selector Reset Source: ctl_amod_g_rst_n
0x217C DDR16SS_CTLPHY_WRAP_CTL_CFG_CTLCFG_DENALI_PI_95 access per field
  [25:24] PI_UPDATE_ERROR_STATUS ro — Identifies the source of any DFI PI-initiated update errors. Value of 1 indicates a timing violation of the associated timing parameter. Bit 1-0: ctrlupd_max_error, ctrlupd_interval_error. Bit 6-2: reserved. READ-ONLY Reset Source: ctl_amod_g_rst_n
  [23:8] PI_TDFI_CTRLUPD_MIN rw — Reports the DFI tCTRLUPD_MIN timing parameter [in DFI clocks], the minimum cycles that dfi_ctrlupd_req must be asserted. Reset Source: ctl_amod_g_rst_n
  [0] PI_CTRLUPD_REQ_PER_AREF_EN rw — Enable an automatic PI initiated update [dfi_ctrlupd_req] after every refresh. Set to 1 to enable. Reset Source: ctl_amod_g_rst_n
0x2180 DDR16SS_CTLPHY_WRAP_CTL_CFG_CTLCFG_DENALI_PI_96 access per field
  [24] PI_BIST_LFSR_PATTERN_DONE ro — BIST operation lfsr pattern, data pattern 1'b0 means the data is useful,1'b1 means next pattern sequence can ingore. READ-ONLY Reset Source: ctl_amod_g_rst_n
  [17:16] PI_BIST_RESULT ro — BIST operation status [pass/fail]. Bit [0] indicates data check status and bit [1] indicates address check status. Value of 1 is a passing result. READ-ONLY Reset Source: ctl_amod_g_rst_n
  [8] PI_BIST_GO rw — Initiate a BIST operation. Set to 1 to trigger. Reset Source: ctl_amod_g_rst_n
  [2:0] PI_TDFI_PARIN_LAT rw — Defines the DFI tPARIN_LAT timing parameter [in DFI PHY clocks], the maximum cycles between a DFI command and a dfi_parity_in signal assertion. Reset Source: ctl_amod_g_rst_n
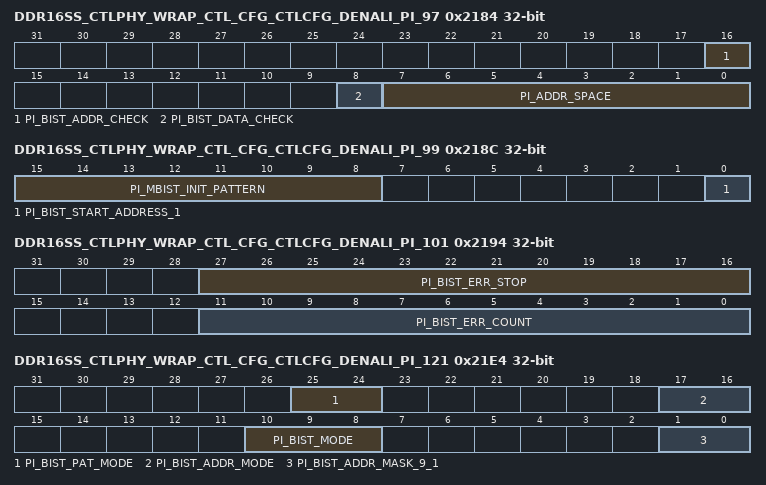
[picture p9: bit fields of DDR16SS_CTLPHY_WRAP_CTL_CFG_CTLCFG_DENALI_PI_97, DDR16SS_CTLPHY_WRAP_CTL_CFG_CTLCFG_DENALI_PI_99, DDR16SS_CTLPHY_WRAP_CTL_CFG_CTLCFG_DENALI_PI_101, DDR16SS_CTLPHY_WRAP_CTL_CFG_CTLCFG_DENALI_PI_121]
0x2184 DDR16SS_CTLPHY_WRAP_CTL_CFG_CTLCFG_DENALI_PI_97
  [16] PI_BIST_ADDR_CHECK — Enable address checking with BIST operation. Set to 1 to enable. Reset Source: ctl_amod_g_rst_n
  [8] PI_BIST_DATA_CHECK — Enable data checking with BIST operation. Set to 1 to enable. Reset Source: ctl_amod_g_rst_n
  [7:0] PI_ADDR_SPACE — Sets the number of address bits to check during BIST operation. The end address of BIST is start_address+[1 shifted up by PI_ADDR_SPACE]-1. The end address should not beyond the actual memory address range. Reset Source: ctl_amod_g_rst_n
0x2188 DDR16SS_CTLPHY_WRAP_CTL_CFG_CTLCFG_DENALI_PI_98
  [31:0] PI_BIST_START_ADDRESS_0 — Start BIST checking at this address. Reset Source: ctl_amod_g_rst_n
0x218C DDR16SS_CTLPHY_WRAP_CTL_CFG_CTLCFG_DENALI_PI_99
  [15:8] PI_MBIST_INIT_PATTERN — PI mbist data check, random lfsr pattern mode init pattern seed. Reset Source: ctl_amod_g_rst_n
  [0] PI_BIST_START_ADDRESS_1 — Start BIST checking at this address. Reset Source: ctl_amod_g_rst_n
0x2190 DDR16SS_CTLPHY_WRAP_CTL_CFG_CTLCFG_DENALI_PI_100
  [31:0] PI_BIST_DATA_MASK — Mask applied to data for BIST error checking. Bit [0] controls memory data path bit [0], bit [1] controls memory data path bit [1], etc. The mask range is the data transfer size in each memory clock cycle [The data on a rising edge and a failing edge]. Set each bit to 1 to mask. Reset Source: ctl_amod_g_rst_n
0x2194 DDR16SS_CTLPHY_WRAP_CTL_CFG_CTLCFG_DENALI_PI_101 access per field
  [27:16] PI_BIST_ERR_STOP rw — Defines the maximum number of error occurrences allowed prior to quitting when the BIST_TEST_MODE parameter is set to 1, 2 or 3. A value of 0 will allow the test to run to completion. Reset Source: ctl_amod_g_rst_n
  [11:0] PI_BIST_ERR_COUNT ro — Indicates the number of BIST errors found when the BIST_TEST_MODE parameter is set to 1, 2 or 3. READ-ONLY Reset Source: ctl_amod_g_rst_n
0x2198 DDR16SS_CTLPHY_WRAP_CTL_CFG_CTLCFG_DENALI_PI_102
  [31:0] PI_BIST_ADDR_MASK_0_0 — Defines an address to be masked during the BIST operation.. Reset Source: ctl_amod_g_rst_n
0x219C DDR16SS_CTLPHY_WRAP_CTL_CFG_CTLCFG_DENALI_PI_103
  [1:0] PI_BIST_ADDR_MASK_0_1 — Defines an address to be masked during the BIST operation.. Reset Source: ctl_amod_g_rst_n
0x21A0 DDR16SS_CTLPHY_WRAP_CTL_CFG_CTLCFG_DENALI_PI_104
  [31:0] PI_BIST_ADDR_MASK_1_0 — Defines an address to be masked during the BIST operation.. Reset Source: ctl_amod_g_rst_n
0x21A4 DDR16SS_CTLPHY_WRAP_CTL_CFG_CTLCFG_DENALI_PI_105
  [1:0] PI_BIST_ADDR_MASK_1_1 — Defines an address to be masked during the BIST operation.. Reset Source: ctl_amod_g_rst_n
0x21A8 DDR16SS_CTLPHY_WRAP_CTL_CFG_CTLCFG_DENALI_PI_106
  [31:0] PI_BIST_ADDR_MASK_2_0 — Defines an address to be masked during the BIST operation.. Reset Source: ctl_amod_g_rst_n
0x21AC DDR16SS_CTLPHY_WRAP_CTL_CFG_CTLCFG_DENALI_PI_107
  [1:0] PI_BIST_ADDR_MASK_2_1 — Defines an address to be masked during the BIST operation.. Reset Source: ctl_amod_g_rst_n
0x21B0 DDR16SS_CTLPHY_WRAP_CTL_CFG_CTLCFG_DENALI_PI_108
  [31:0] PI_BIST_ADDR_MASK_3_0 — Defines an address to be masked during the BIST operation.. Reset Source: ctl_amod_g_rst_n
0x21B4 DDR16SS_CTLPHY_WRAP_CTL_CFG_CTLCFG_DENALI_PI_109
  [1:0] PI_BIST_ADDR_MASK_3_1 — Defines an address to be masked during the BIST operation.. Reset Source: ctl_amod_g_rst_n
0x21B8 DDR16SS_CTLPHY_WRAP_CTL_CFG_CTLCFG_DENALI_PI_110
  [31:0] PI_BIST_ADDR_MASK_4_0 — Defines an address to be masked during the BIST operation.. Reset Source: ctl_amod_g_rst_n
0x21BC DDR16SS_CTLPHY_WRAP_CTL_CFG_CTLCFG_DENALI_PI_111
  [1:0] PI_BIST_ADDR_MASK_4_1 — Defines an address to be masked during the BIST operation.. Reset Source: ctl_amod_g_rst_n
0x21C0 DDR16SS_CTLPHY_WRAP_CTL_CFG_CTLCFG_DENALI_PI_112
  [31:0] PI_BIST_ADDR_MASK_5_0 — Defines an address to be masked during the BIST operation.. Reset Source: ctl_amod_g_rst_n
0x21C4 DDR16SS_CTLPHY_WRAP_CTL_CFG_CTLCFG_DENALI_PI_113
  [1:0] PI_BIST_ADDR_MASK_5_1 — Defines an address to be masked during the BIST operation.. Reset Source: ctl_amod_g_rst_n
0x21C8 DDR16SS_CTLPHY_WRAP_CTL_CFG_CTLCFG_DENALI_PI_114
  [31:0] PI_BIST_ADDR_MASK_6_0 — Defines an address to be masked during the BIST operation.. Reset Source: ctl_amod_g_rst_n
0x21CC DDR16SS_CTLPHY_WRAP_CTL_CFG_CTLCFG_DENALI_PI_115
  [1:0] PI_BIST_ADDR_MASK_6_1 — Defines an address to be masked during the BIST operation.. Reset Source: ctl_amod_g_rst_n
0x21D0 DDR16SS_CTLPHY_WRAP_CTL_CFG_CTLCFG_DENALI_PI_116
  [31:0] PI_BIST_ADDR_MASK_7_0 — Defines an address to be masked during the BIST operation.. Reset Source: ctl_amod_g_rst_n
0x21D4 DDR16SS_CTLPHY_WRAP_CTL_CFG_CTLCFG_DENALI_PI_117
  [1:0] PI_BIST_ADDR_MASK_7_1 — Defines an address to be masked during the BIST operation.. Reset Source: ctl_amod_g_rst_n
0x21D8 DDR16SS_CTLPHY_WRAP_CTL_CFG_CTLCFG_DENALI_PI_118
  [31:0] PI_BIST_ADDR_MASK_8_0 — Defines an address to be masked during the BIST operation.. Reset Source: ctl_amod_g_rst_n
0x21DC DDR16SS_CTLPHY_WRAP_CTL_CFG_CTLCFG_DENALI_PI_119
  [1:0] PI_BIST_ADDR_MASK_8_1 — Defines an address to be masked during the BIST operation.. Reset Source: ctl_amod_g_rst_n
0x21E0 DDR16SS_CTLPHY_WRAP_CTL_CFG_CTLCFG_DENALI_PI_120
  [31:0] PI_BIST_ADDR_MASK_9_0 — Defines an address to be masked during the BIST operation.. Reset Source: ctl_amod_g_rst_n
0x21E4 DDR16SS_CTLPHY_WRAP_CTL_CFG_CTLCFG_DENALI_PI_121
  [25:24] PI_BIST_PAT_MODE — Sets the pattern mode of BIST. 'b00 indicates using built-in pattern. 'b01 indicates checkerboard pattern, each data transfer inverts the last data transfer based on the built-in pattern. 'b10 indicates using both user pattern and built-in pattern. 'b11 indicates using pi lfsr random pattern. Reset Source: ctl_amod_g_rst_n
  [17:16] PI_BIST_ADDR_MODE — Sets the address traversing order of BIST. 'b00 indicates fast column order [burst-column-bank-row-rank]. 'b01 indicates fast row order [burst-row-column-bank-rank]. 'b10 indicates fast bank order [burst-bank-column-row-rank]. Reset Source: ctl_amod_g_rst_n
  [10:8] PI_BIST_MODE — Sets the BIST data checking mode. 'b00 indicates MOVI13N mode. 'b01 indicates March C mode. 'b10 indicates GALPAT mode. 'b11 indicates PRBS mode. 'b100 indicates programmable March data check mode. Reset Source: ctl_amod_g_rst_n
  [1:0] PI_BIST_ADDR_MASK_9_1 — Defines an address to be masked during the BIST operation.. Reset Source: ctl_amod_g_rst_n
0x21E8 DDR16SS_CTLPHY_WRAP_CTL_CFG_CTLCFG_DENALI_PI_122
  [31:0] PI_BIST_USER_PAT_0 — Sets the user-specified pattern of BIST. Reset Source: ctl_amod_g_rst_n
0x21EC DDR16SS_CTLPHY_WRAP_CTL_CFG_CTLCFG_DENALI_PI_123
  [31:0] PI_BIST_USER_PAT_1 — Sets the user-specified pattern of BIST. Reset Source: ctl_amod_g_rst_n
0x21F0 DDR16SS_CTLPHY_WRAP_CTL_CFG_CTLCFG_DENALI_PI_124
  [5:0] PI_BIST_PAT_NUM — Sets the max used pattern number of BIST from a total of 8 built-in patterns. Ex. set to 3, The BIST would use pattern 1, 2 and 3. Reset Source: ctl_amod_g_rst_n
{0x2000+4i} DDR16SS_CTLPHY_WRAP_CTL_CFG_CTLCFG_DENALI_PI_{i} (i=125..132)
  [29:0] PI_BIST_STAGE_{i-125} — Sets the programmable algorithm of each stage X when pi_bist_mmode = 'h4. Reset Source: ctl_amod_g_rst_n
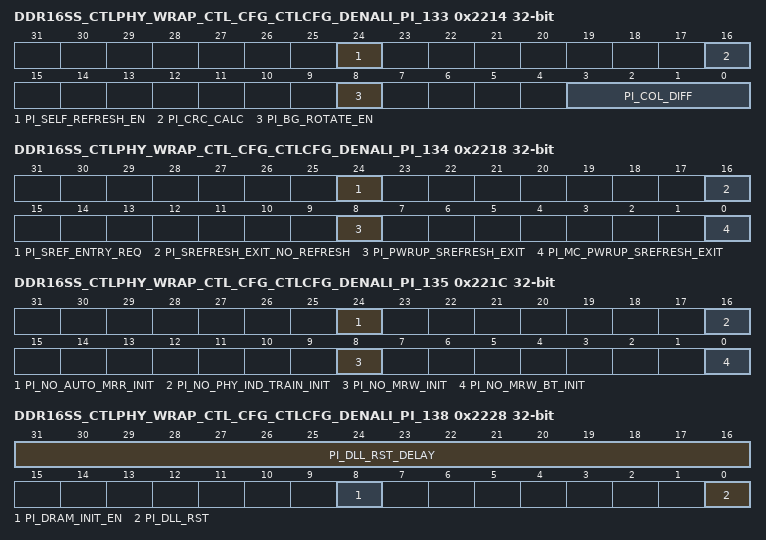
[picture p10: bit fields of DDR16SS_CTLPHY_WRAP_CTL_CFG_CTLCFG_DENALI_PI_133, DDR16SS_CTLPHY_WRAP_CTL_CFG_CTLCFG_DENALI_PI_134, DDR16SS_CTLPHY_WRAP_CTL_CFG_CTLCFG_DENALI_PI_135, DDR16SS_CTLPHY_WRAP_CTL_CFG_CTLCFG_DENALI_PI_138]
0x2214 DDR16SS_CTLPHY_WRAP_CTL_CFG_CTLCFG_DENALI_PI_133
  [24] PI_SELF_REFRESH_EN — Control for PI to enable self refresh mode. Set to 1 to enable. Reset Source: ctl_amod_g_rst_n
  [16] PI_CRC_CALC — Defines where CRC is performed; set to 1 for PI responsibility or clear to 0 for PHY responsibility. Reset Source: ctl_amod_g_rst_n
  [8] PI_BG_ROTATE_EN — Enable bank group rotation. Set to 1 to enable. Reset Source: ctl_amod_g_rst_n
  [3:0] PI_COL_DIFF — Difference between number of column pins available and number being used. Reset Source: ctl_amod_g_rst_n
0x2218 DDR16SS_CTLPHY_WRAP_CTL_CFG_CTLCFG_DENALI_PI_134 access per field
  [24] PI_SREF_ENTRY_REQ wo — In PI power up data retention, PI can issued sref entry command. WRITE-ONLY Reset Source: ctl_amod_g_rst_n
  [16] PI_SREFRESH_EXIT_NO_REFRESH rw — Disables the automatic refresh request associated with self-refresh exit. Set to 1 to disable. Reset Source: ctl_amod_g_rst_n
  [8] PI_PWRUP_SREFRESH_EXIT rw — PI control powerup via self-refresh instead of full memory initialization. Set to 1 to enable. Reset Source: ctl_amod_g_rst_n
  [0] PI_MC_PWRUP_SREFRESH_EXIT rw — It indicates MC control powerup via self-refresh instead of full memory initialization. Set to 1 to enable. Reset Source: ctl_amod_g_rst_n
0x221C DDR16SS_CTLPHY_WRAP_CTL_CFG_CTLCFG_DENALI_PI_135
  [24] PI_NO_AUTO_MRR_INIT — Disable MRR commands during initialization. Set to 1 to disable. Reset Source: ctl_amod_g_rst_n
  [16] PI_NO_PHY_IND_TRAIN_INIT — Disable PHY Independent Training during initialization. Set to 1 to disable. Reset Source: ctl_amod_g_rst_n
  [8] PI_NO_MRW_INIT — Disable MRW commands after training during initialization. Set to 1 to disable. Reset Source: ctl_amod_g_rst_n
  [0] PI_NO_MRW_BT_INIT — Disable MRW commands before training during initialization. Set to 1 to disable. Reset Source: ctl_amod_g_rst_n
0x2220 DDR16SS_CTLPHY_WRAP_CTL_CFG_CTLCFG_DENALI_PI_136
  [31:0] PI_TRST_PWRON — Duration of memory reset during power-on initialization. Reset Source: ctl_amod_g_rst_n
0x2224 DDR16SS_CTLPHY_WRAP_CTL_CFG_CTLCFG_DENALI_PI_137
  [31:0] PI_CKE_INACTIVE — Number of cycles after reset before CKE will be active. Reset Source: ctl_amod_g_rst_n
0x2228 DDR16SS_CTLPHY_WRAP_CTL_CFG_CTLCFG_DENALI_PI_138
  [31:16] PI_DLL_RST_DELAY — Minimum cycles required for DLL reset signal dll_rst_n to be held. Reset Source: ctl_amod_g_rst_n
  [8] PI_DRAM_INIT_EN — Control for the initialization of DRAM by the PI. Reset Source: ctl_amod_g_rst_n
  [0] PI_DLL_RST — Enables use of the DLL reset [dll_rst_n]. Reset Source: ctl_amod_g_rst_n
0x222C DDR16SS_CTLPHY_WRAP_CTL_CFG_CTLCFG_DENALI_PI_139
  [7:0] PI_DLL_RST_ADJ_DLY — Minimum cycles after setting master delay in DLL until the DLL reset signal dll_rst_n may be asserted. Reset Source: ctl_amod_g_rst_n
0x2230 DDR16SS_CTLPHY_WRAP_CTL_CFG_CTLCFG_DENALI_PI_140
  [25:0] PI_WRITE_MODEREG — Write memory mode register data to the DRAMs. Bits [7:0] define the memory mode register number if bit [23] is set, bits [15:8] define the chip select if bit [24] is clear, bits [23:16] define which memory mode register/s to write, bit [24] defines whether all chip selects will be written, and bit [25] triggers the write. Reset Source: ctl_amod_g_rst_n
0x2234 DDR16SS_CTLPHY_WRAP_CTL_CFG_CTLCFG_DENALI_PI_141 ro
  [7:0] PI_MRW_STATUS — Write memory mode register status. Bit [0] set indicates a WRITE_MODEREG parameter programming error. Bit [1] set indicates a PASR error. Bit [2] is Reserved. Bit [3] set indicates a self refresh or deep power down error. Bit [4] set indicates that a write to MR3 or MR11 was attempted [write_modereg bit [25] was asserted with bit [17] set, or bit [23] was asserted with bits [7:0] defining MR3 or MR11] during tZQCAL after a ZQ calibration start command. READ-ONLY Reset Source: ctl_amod_g_rst_n
0x2238 DDR16SS_CTLPHY_WRAP_CTL_CFG_CTLCFG_DENALI_PI_142
  [16:0] PI_READ_MODEREG — Read the specified memory mode register from specified chip when start bit set. Bits [7:0] define the memory mode register and bits [15:8] define the chip select. Set bit [16] to 1 to trigger. Reset Source: ctl_amod_g_rst_n
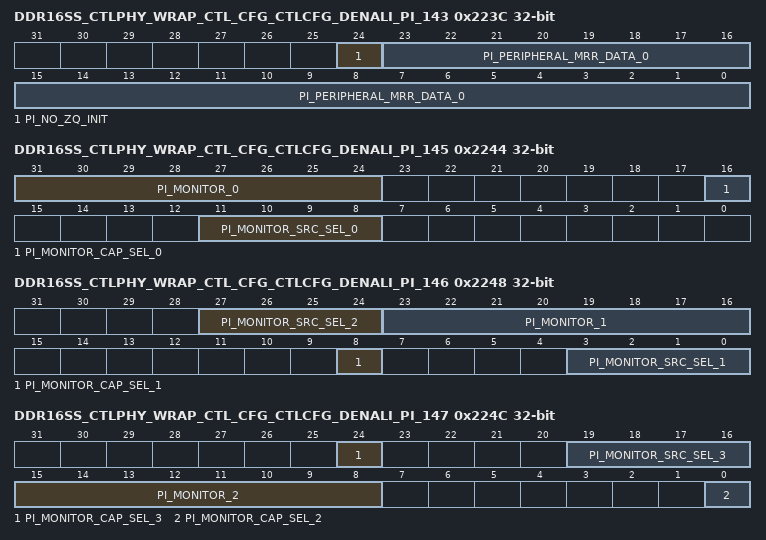
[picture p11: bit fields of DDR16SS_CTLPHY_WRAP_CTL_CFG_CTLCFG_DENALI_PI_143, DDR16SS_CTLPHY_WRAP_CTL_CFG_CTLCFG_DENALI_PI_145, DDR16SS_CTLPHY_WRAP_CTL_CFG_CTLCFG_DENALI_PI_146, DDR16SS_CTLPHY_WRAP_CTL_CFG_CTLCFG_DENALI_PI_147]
0x223C DDR16SS_CTLPHY_WRAP_CTL_CFG_CTLCFG_DENALI_PI_143 access per field
  [24] PI_NO_ZQ_INIT rw — Disable ZQ operations during initialization. Set to 1 to disable. Reset Source: ctl_amod_g_rst_n
  [23:0] PI_PERIPHERAL_MRR_DATA_0 ro — Data and chip returned from memory mode register read requested by the READ_MODEREG parameter, Bits [15:0] define MRR data, [23:16] define the chip select. READ-ONLY Reset Source: ctl_amod_g_rst_n
0x2240 DDR16SS_CTLPHY_WRAP_CTL_CFG_CTLCFG_DENALI_PI_144 ro
  [16] PI_ZQ_REQ_PENDING — Indicates that a ZQ command is currently in progress or waiting to run. When this is asserted, no writes to ZQ_REQ should occur. READ-ONLY Reset Source: ctl_amod_g_rst_n
0x2244 DDR16SS_CTLPHY_WRAP_CTL_CFG_CTLCFG_DENALI_PI_145 access per field
  [31:24] PI_MONITOR_0 ro — Monitor register 0. READ-ONLY. Reset Source: ctl_amod_g_rst_n
  [16] PI_MONITOR_CAP_SEL_0 rw — Selection of captures for pi_monitor_0. Reset Source: ctl_amod_g_rst_n
  [11:8] PI_MONITOR_SRC_SEL_0 rw — Selection of sources for pi_monitor_0. Reset Source: ctl_amod_g_rst_n
0x2248 DDR16SS_CTLPHY_WRAP_CTL_CFG_CTLCFG_DENALI_PI_146 access per field
  [27:24] PI_MONITOR_SRC_SEL_2 rw — Selection of sources for pi_monitor_2. Reset Source: ctl_amod_g_rst_n
  [23:16] PI_MONITOR_1 ro — Monitor register 1. READ-ONLY. Reset Source: ctl_amod_g_rst_n
  [8] PI_MONITOR_CAP_SEL_1 rw — Selection of captures for pi_monitor_1. Reset Source: ctl_amod_g_rst_n
  [3:0] PI_MONITOR_SRC_SEL_1 rw — Selection of sources for pi_monitor_1. Reset Source: ctl_amod_g_rst_n
0x224C DDR16SS_CTLPHY_WRAP_CTL_CFG_CTLCFG_DENALI_PI_147 access per field
  [24] PI_MONITOR_CAP_SEL_3 rw — Selection of captures for pi_monitor_3. Reset Source: ctl_amod_g_rst_n
  [19:16] PI_MONITOR_SRC_SEL_3 rw — Selection of sources for pi_monitor_3. Reset Source: ctl_amod_g_rst_n
  [15:8] PI_MONITOR_2 ro — Monitor register 2. READ-ONLY. Reset Source: ctl_amod_g_rst_n
  [0] PI_MONITOR_CAP_SEL_2 rw — Selection of captures for pi_monitor_2. Reset Source: ctl_amod_g_rst_n
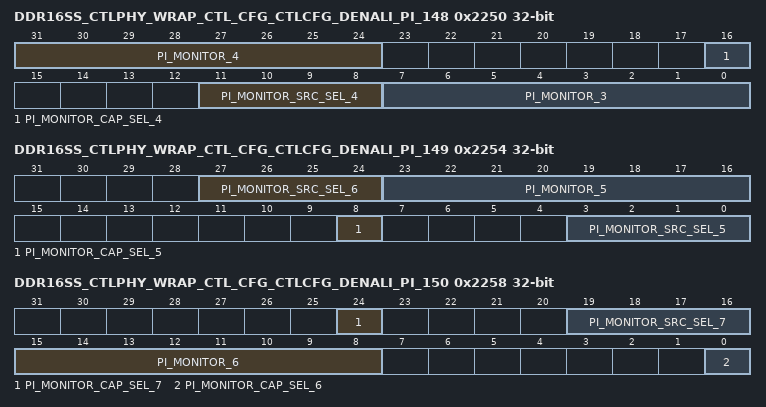
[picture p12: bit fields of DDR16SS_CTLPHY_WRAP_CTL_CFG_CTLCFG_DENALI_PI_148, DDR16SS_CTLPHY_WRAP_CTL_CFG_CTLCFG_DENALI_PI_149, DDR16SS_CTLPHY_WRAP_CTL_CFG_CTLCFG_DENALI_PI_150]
0x2250 DDR16SS_CTLPHY_WRAP_CTL_CFG_CTLCFG_DENALI_PI_148 access per field
  [31:24] PI_MONITOR_4 ro — Monitor register 4. READ-ONLY. Reset Source: ctl_amod_g_rst_n
  [16] PI_MONITOR_CAP_SEL_4 rw — Selection of captures for pi_monitor_4. Reset Source: ctl_amod_g_rst_n
  [11:8] PI_MONITOR_SRC_SEL_4 rw — Selection of sources for pi_monitor_4. Reset Source: ctl_amod_g_rst_n
  [7:0] PI_MONITOR_3 ro — Monitor register 3. READ-ONLY. Reset Source: ctl_amod_g_rst_n
0x2254 DDR16SS_CTLPHY_WRAP_CTL_CFG_CTLCFG_DENALI_PI_149 access per field
  [27:24] PI_MONITOR_SRC_SEL_6 rw — Selection of sources for pi_monitor_6. Reset Source: ctl_amod_g_rst_n
  [23:16] PI_MONITOR_5 ro — Monitor register 5. READ-ONLY. Reset Source: ctl_amod_g_rst_n
  [8] PI_MONITOR_CAP_SEL_5 rw — Selection of captures for pi_monitor_5. Reset Source: ctl_amod_g_rst_n
  [3:0] PI_MONITOR_SRC_SEL_5 rw — Selection of sources for pi_monitor_5. Reset Source: ctl_amod_g_rst_n
0x2258 DDR16SS_CTLPHY_WRAP_CTL_CFG_CTLCFG_DENALI_PI_150 access per field
  [24] PI_MONITOR_CAP_SEL_7 rw — Selection of captures for pi_monitor_7. Reset Source: ctl_amod_g_rst_n
  [19:16] PI_MONITOR_SRC_SEL_7 rw — Selection of sources for pi_monitor_7. Reset Source: ctl_amod_g_rst_n
  [15:8] PI_MONITOR_6 ro — Monitor register 6. READ-ONLY. Reset Source: ctl_amod_g_rst_n
  [0] PI_MONITOR_CAP_SEL_6 rw — Selection of captures for pi_monitor_6. Reset Source: ctl_amod_g_rst_n
0x225C DDR16SS_CTLPHY_WRAP_CTL_CFG_CTLCFG_DENALI_PI_151 ro
  [7:0] PI_MONITOR_7 — Monitor register 7. READ-ONLY. Reset Source: ctl_amod_g_rst_n
0x2260 DDR16SS_CTLPHY_WRAP_CTL_CFG_CTLCFG_DENALI_PI_152 wo
  [7:0] PI_MONITOR_STROBE — Strobe the pi_monitor once. Every bit corresponds respectively with a pi_monitor. WRITE-ONLY Reset Source: ctl_amod_g_rst_n
